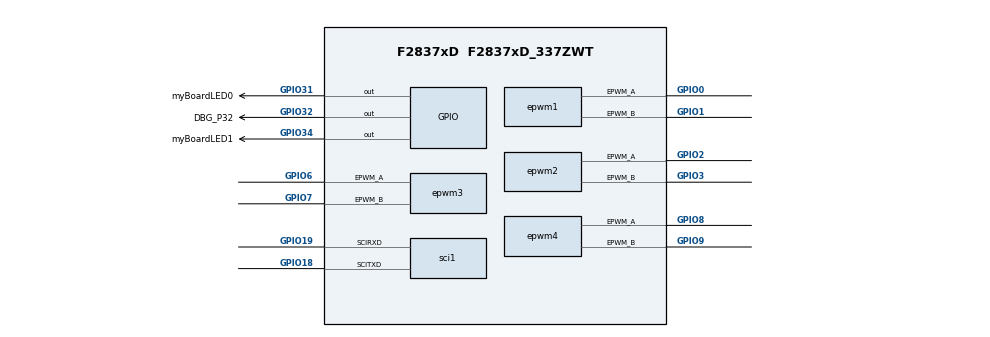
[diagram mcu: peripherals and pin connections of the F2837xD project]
/**
 * @cliArgs --device "F2837xD" --part "F2837xD_337ZWT" --package "F2837xD_337ZWT" --context "CPU1" --product "C2000WARE@5.05.00.00"
 * @versions {"tool":"1.24.1+4189"}
 */

/**
 * Import the modules used in this configuration.
 */
const adc       = scripting.addModule("/driverlib/adc.js", {}, false);
const adc1      = adc.addInstance();
const led       = scripting.addModule("/driverlib/board_components/led", {}, false);
const led1      = led.addInstance();
const led2      = led.addInstance();
const cputimer  = scripting.addModule("/driverlib/cputimer.js", {}, false);
const cputimer1 = cputimer.addInstance();
const ecap      = scripting.addModule("/driverlib/ecap.js", {}, false);
const ecap1     = ecap.addInstance();
const epwm      = scripting.addModule("/driverlib/epwm.js", {}, false);
const epwm1     = epwm.addInstance();
const epwm2     = epwm.addInstance();
const epwm3     = epwm.addInstance();
const epwm4     = epwm.addInstance();
const flash     = scripting.addModule("/driverlib/flash.js", {}, false);
const flash1    = flash.addInstance();
const gpio      = scripting.addModule("/driverlib/gpio.js", {}, false);
const gpio3     = gpio.addInstance();
const sci       = scripting.addModule("/driverlib/sci.js", {}, false);
const sci1      = sci.addInstance();

/**
 * Write custom configuration values to the imported modules.
 */
adc1.$name                          = "myADC0";
adc1.adcClockPrescaler              = "ADC_CLK_DIV_2_0";
adc1.soc2Channel                    = "ADC_CH_ADCIN2";
adc1.soc1Channel                    = "ADC_CH_ADCIN1";
adc1.interruptPulseMode             = "ADC_PULSE_END_OF_CONV";
adc1.registerInterrupts             = ["1"];
adc1.enableBurstMode                = true;
adc1.enabledInts                    = ["ADC_INT_NUMBER1"];
adc1.enableInterrupt1               = true;
adc1.enableInterrupt1ContinuousMode = true;
adc1.burstTrigger                   = "ADC_TRIGGER_EPWM1_SOCA";
adc1.soc0Trigger                    = "ADC_TRIGGER_EPWM1_SOCA";
adc1.soc1Trigger                    = "ADC_TRIGGER_EPWM1_SOCA";
adc1.soc2Trigger                    = "ADC_TRIGGER_EPWM1_SOCA";
adc1.burstSize                      = 15;
adc1.soc1SampleWindow               = 100;
adc1.soc2SampleWindow               = 100;
adc1.soc0SampleWindow               = 100;
adc1.interrupt1SOCSource            = "ADC_SOC_NUMBER15";
adc1.enabledSOCs                    = ["ADC_SOC_NUMBER0","ADC_SOC_NUMBER1","ADC_SOC_NUMBER2","ADC_SOC_NUMBER3"];
adc1.soc3Trigger                    = "ADC_TRIGGER_EPWM1_SOCA";
adc1.soc3SampleWindow               = 100;
adc1.soc3Channel                    = "ADC_CH_ADCIN13";
adc1.adcInt1.enableInterrupt        = true;
scripting.suppress("The maximum frequency of ADC for this device is 50MHz\\. ADC Clock Prescaler should be selected accordingly\\.", adc1, "adcClockPrescaler");

led1.$name                  = "myBoardLED0";
led1.gpio.$name             = "OPLED_BL";
led1.gpio.writeInitialValue = true;
led1.gpio.initialValue      = 1;
led1.gpio.gpioPin.$assign   = "GPIO31";

led2.$name                  = "myBoardLED1";
led2.gpio.$name             = "OPLED_RD";
led2.gpio.writeInitialValue = true;
led2.gpio.initialValue      = 1;
led2.gpio.gpioPin.$assign   = "GPIO34";

const divider3       = system.clockTree["EPWMCLKDIV"];
divider3.divideValue = 1;

const divider5       = system.clockTree["SYSCLKDIVSEL"];
divider5.divideValue = 4;

cputimer1.$name                    = "myCPUTIMER0";
cputimer1.enableInterrupt          = true;
cputimer1.registerInterrupts       = true;
cputimer1.startTimer               = true;
cputimer1.timerPeriod              = 99999;
cputimer1.timerInt.enableInterrupt = true;

ecap1.$name                   = "myECAP0";
ecap1.registerInterrupts      = true;
ecap1.enableInterrupt         = true;
ecap1.ecapMode                = "APWM";
ecap1.interruptSourceAPWM     = ["ECAP_ISR_SOURCE_COUNTER_PERIOD"];
ecap1.apwmPeriod              = 13000;
ecap1.ecapInt.enableInterrupt = true;

epwm1.epwmTimebase_counterMode                                 = "EPWM_COUNTER_MODE_UP";
epwm1.epwmTimebase_period                                      = 999;
epwm1.epwmTimebase_syncOutPulseMode                            = "EPWM_SYNC_OUT_PULSE_ON_COUNTER_ZERO";
epwm1.$name                                                    = "myEPWM1";
epwm1.epwmDeadband_polarityRED                                 = "EPWM_DB_POLARITY_ACTIVE_LOW";
epwm1.epwmDeadband_polarityFED                                 = "EPWM_DB_POLARITY_ACTIVE_LOW";
epwm1.epwmCounterCompare_cmpA                                  = 250;
epwm1.epwmCounterCompare_cmpB                                  = 350;
epwm1.epwmActionQualifier_EPWM_AQ_OUTPUT_A_ON_TIMEBASE_ZERO    = "EPWM_AQ_OUTPUT_HIGH";
epwm1.epwmActionQualifier_EPWM_AQ_OUTPUT_A_ON_TIMEBASE_UP_CMPA = "EPWM_AQ_OUTPUT_LOW";
epwm1.epwmActionQualifier_EPWM_AQ_OUTPUT_B_ON_TIMEBASE_ZERO    = "EPWM_AQ_OUTPUT_HIGH";
epwm1.epwmActionQualifier_EPWM_AQ_OUTPUT_B_ON_TIMEBASE_UP_CMPB = "EPWM_AQ_OUTPUT_LOW";
epwm1.epwmEventTrigger_enableInterrupt                         = true;
epwm1.epwmEventTrigger_registerInterrupts                      = true;
epwm1.epwmEventTrigger_interruptSource                         = "EPWM_INT_TBCTR_PERIOD";
epwm1.epwmEventTrigger_interruptEventCount                     = "15";
epwm1.epwmEventTrigger_EPWM_SOC_A_triggerEnable                = true;
epwm1.epwmEventTrigger_EPWM_SOC_A_triggerSource                = "EPWM_SOC_TBCTR_ZERO";
epwm1.epwmEventTrigger_EPWM_SOC_A_triggerEventPrescalar        = "5";
epwm1.epwm.$assign                                             = "EPWM1";
epwm1.epwm.epwm_aPin.$assign                                   = "GPIO0";
epwm1.epwm.epwm_bPin.$assign                                   = "GPIO1";
epwm1.aQual.qualMode                                           = "GPIO_QUAL_ASYNC";
epwm1.bQual.qualMode                                           = "GPIO_QUAL_ASYNC";
epwm1.epwmInt.enableInterrupt                                  = true;

epwm2.$name                         = "myEPWM2";
epwm2.epwmTimebase_counterMode      = "EPWM_COUNTER_MODE_UP";
epwm2.epwmTimebase_period           = 999;
epwm2.epwmTimebase_phaseEnable      = true;
epwm2.epwmTimebase_phaseShift       = 250;
epwm2.epwmTimebase_syncOutPulseMode = "EPWM_SYNC_OUT_PULSE_ON_EPWMxSYNCIN";
epwm2.epwm.$assign                  = "EPWM2";
epwm2.epwm.epwm_aPin.$assign        = "GPIO2";
epwm2.epwm.epwm_bPin.$assign        = "GPIO3";

epwm3.$name                         = "myEPWM4";
epwm3.epwmTimebase_period           = 999;
epwm3.epwmTimebase_phaseEnable      = true;
epwm3.epwmTimebase_counterMode      = "EPWM_COUNTER_MODE_UP";
epwm3.epwmTimebase_phaseShift       = 250;
epwm3.epwmTimebase_syncOutPulseMode = "EPWM_SYNC_OUT_PULSE_ON_EPWMxSYNCIN";
epwm3.epwm.epwm_aPin.$assign        = "GPIO6";
epwm3.epwm.epwm_bPin.$assign        = "GPIO7";

epwm4.$name                         = "myEPWM5";
epwm4.epwmTimebase_period           = 999;
epwm4.epwmTimebase_phaseEnable      = true;
epwm4.epwmTimebase_phaseShift       = 250;
epwm4.epwmTimebase_syncOutPulseMode = "EPWM_SYNC_OUT_PULSE_ON_EPWMxSYNCIN";
epwm4.epwm.$assign                  = "EPWM5";
epwm4.epwm.epwm_aPin.$assign        = "GPIO8";
epwm4.epwm.epwm_bPin.$assign        = "GPIO9";

flash1.$name = "myFMC0";

gpio3.direction       = "GPIO_DIR_MODE_OUT";
gpio3.$name           = "DBG_P32";
gpio3.gpioPin.$assign = "GPIO32";

sci1.selectRegisteredInterrupts = ["registerRxInt","registerTxInt"];
sci1.$name                      = "mySCIB";
sci1.enabledFIFOInterrupts      = ["SCI_INT_RXFF","SCI_INT_TXFF"];
sci1.rxFifo                     = "SCI_FIFO_RX1";
sci1.sci.$assign                = "SCIB";
sci1.sci.scirxdPin.$assign      = "GPIO19";
sci1.sci.scitxdPin.$assign      = "GPIO18";
sci1.rxQual.$name               = "myGPIOQUAL0";
sci1.txQual.$name               = "myGPIOQUAL1";
sci1.sciRXInt.enableInterrupt   = true;
sci1.sciTXInt.enableInterrupt   = true;

/**
 * Pinmux solution for unlocked pins/peripherals. This ensures that minor changes to the automatic solver in a future
 * version of the tool will not impact the pinmux you originally saw.  These lines can be completely deleted in order to
 * re-solve from scratch.
 */
epwm3.epwm.$suggestSolution = "EPWM4";
